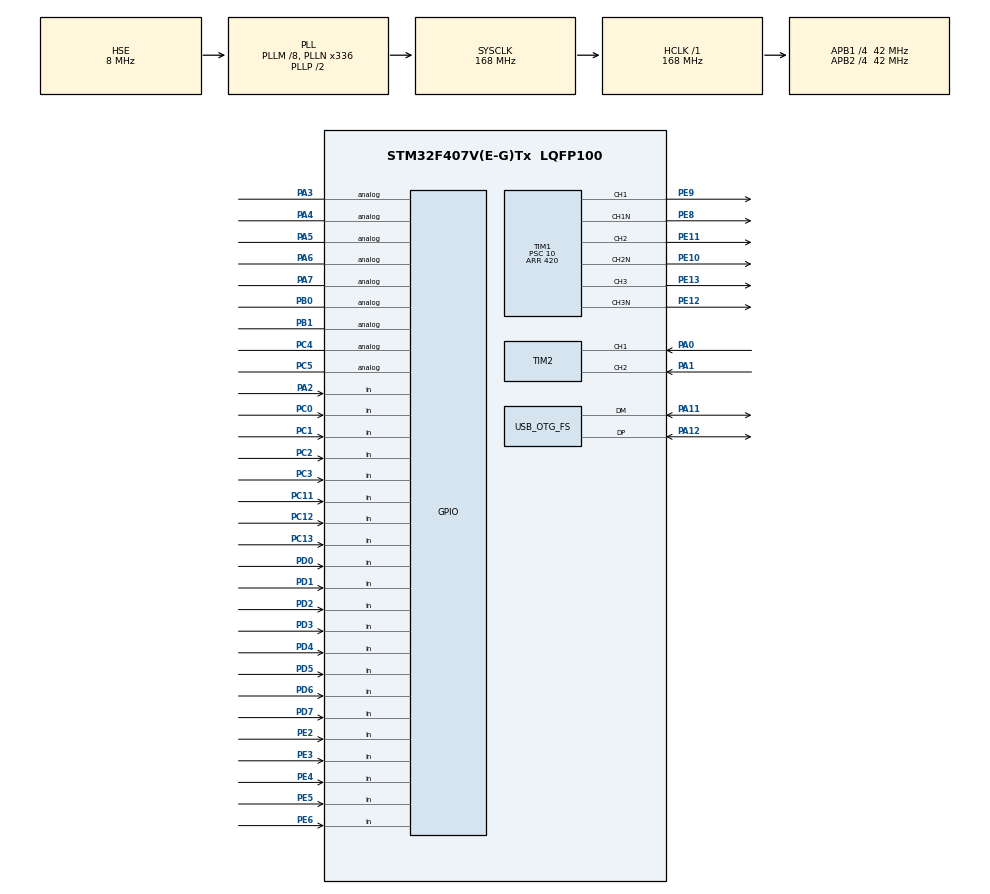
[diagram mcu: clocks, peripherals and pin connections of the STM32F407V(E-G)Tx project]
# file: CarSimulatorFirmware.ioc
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Mcu.Family=STM32F4
Mcu.Name=STM32F407V(E-G)Tx
Mcu.Package=LQFP100
NVIC.OTG_FS_IRQn=true\:0\:0\:false\:false\:true\:false\:true
NVIC.PriorityGroup=NVIC_PRIORITYGROUP_4
NVIC.TIM2_IRQn=true\:0\:0\:false\:false\:true\:true\:true
PA0-WKUP.GPIO_Speed=GPIO_SPEED_FREQ_VERY_HIGH
PA0-WKUP.Signal=S_TIM2_CH1_ETR
PA1.GPIO_Speed=GPIO_SPEED_FREQ_VERY_HIGH
PA1.Signal=S_TIM2_CH2
PA11.Mode=Device_Only
PA11.Signal=USB_OTG_FS_DM
PA12.Mode=Device_Only
PA12.Signal=USB_OTG_FS_DP
PA2.GPIO_PuPd=GPIO_NOPULL
PA2.Signal=GPIO_Input
PA3.Signal=GPIO_Analog
PA4.Signal=GPIO_Analog
PA5.Signal=GPIO_Analog
PA6.Signal=GPIO_Analog
PA7.Signal=GPIO_Analog
PB0.Signal=GPIO_Analog
PB1.Signal=GPIO_Analog
PC0.Signal=GPIO_Input
PC1.Signal=GPIO_Input
PC11.Signal=GPIO_Input
PC12.Signal=GPIO_Input
PC13-ANTI_TAMP.Signal=GPIO_Input
PC2.Signal=GPIO_Input
PC3.Signal=GPIO_Input
PC4.Signal=GPIO_Analog
PC5.Signal=GPIO_Analog
PD0.Signal=GPIO_Input
PD1.Signal=GPIO_Input
PD2.Signal=GPIO_Input
PD3.Signal=GPIO_Input
PD4.Signal=GPIO_Input
PD5.Signal=GPIO_Input
PD6.Signal=GPIO_Input
PD7.Signal=GPIO_Input
PE10.GPIO_Speed=GPIO_SPEED_FREQ_VERY_HIGH
PE10.Mode=PWM Generation2 CH2 CH2N
PE10.Signal=TIM1_CH2N
PE11.GPIO_Speed=GPIO_SPEED_FREQ_VERY_HIGH
PE11.Signal=S_TIM1_CH2
PE12.GPIO_Speed=GPIO_SPEED_FREQ_VERY_HIGH
PE12.Mode=PWM Generation3 CH3 CH3N
PE12.Signal=TIM1_CH3N
PE13.GPIO_Speed=GPIO_SPEED_FREQ_VERY_HIGH
PE13.Signal=S_TIM1_CH3
PE2.Signal=GPIO_Input
PE3.Signal=GPIO_Input
PE4.Signal=GPIO_Input
PE5.Signal=GPIO_Input
PE6.Signal=GPIO_Input
PE8.GPIO_Speed=GPIO_SPEED_FREQ_VERY_HIGH
PE8.Mode=PWM Generation1 CH1 CH1N
PE8.Signal=TIM1_CH1N
PE9.GPIO_PuPd=GPIO_NOPULL
PE9.GPIO_Speed=GPIO_SPEED_FREQ_VERY_HIGH
PE9.Signal=S_TIM1_CH1
PH0-OSC_IN.Mode=HSE-External-Oscillator
PH0-OSC_IN.Signal=RCC_OSC_IN
PH1-OSC_OUT.Mode=HSE-External-Oscillator
PH1-OSC_OUT.Signal=RCC_OSC_OUT
ProjectManager.HeapSize=0x200
ProjectManager.StackSize=0x400
ProjectManager.TargetToolchain=STM32CubeIDE
RCC.48MHZClocksFreq_Value=48000000
RCC.AHBFreq_Value=168000000
RCC.APB1CLKDivider=RCC_HCLK_DIV4
RCC.APB1Freq_Value=42000000
RCC.APB1TimFreq_Value=84000000
RCC.APB2CLKDivider=RCC_HCLK_DIV4
RCC.APB2Freq_Value=42000000
RCC.APB2TimFreq_Value=84000000
RCC.CortexFreq_Value=168000000
RCC.HCLKFreq_Value=168000000
RCC.HSE_VALUE=8000000
RCC.HSI_VALUE=16000000
RCC.LSE_VALUE=32768
RCC.PLLM=8
RCC.PLLN=336
RCC.PLLQ=7
RCC.SYSCLKFreq_VALUE=168000000
RCC.SYSCLKSource=RCC_SYSCLKSOURCE_PLLCLK
RCC.VCOOutputFreq_Value=336000000
SH.S_TIM1_CH1.0=TIM1_CH1,PWM Generation1 CH1 CH1N
SH.S_TIM1_CH2.0=TIM1_CH2,PWM Generation2 CH2 CH2N
SH.S_TIM1_CH3.0=TIM1_CH3,PWM Generation3 CH3 CH3N
SH.S_TIM2_CH1_ETR.0=TIM2_CH1,Encoder_Interface
SH.S_TIM2_CH2.0=TIM2_CH2,Encoder_Interface
TIM1.Channel-PWM\ Generation1\ CH1\ CH1N=TIM_CHANNEL_1
TIM1.Channel-PWM\ Generation2\ CH2\ CH2N=TIM_CHANNEL_2
TIM1.Channel-PWM\ Generation3\ CH3\ CH3N=TIM_CHANNEL_3
TIM1.Period=420
TIM1.Prescaler=10
TIM2.EncoderMode=TIM_ENCODERMODE_TI1
USB_DEVICE.CLASS_NAME_FS=CUSTOM_HID
USB_DEVICE.MANUFACTURER_STRING-CUSTOM_HID_FS=CZM Simluator
USB_DEVICE.PID_CUSTOMHID_FS=2020 
USB_DEVICE.PRODUCT_STRING_CUSTOMHID_FS=Car Simulator Firmware
USB_DEVICE.USBD_CUSTOMHID_OUTREPORT_BUF_SIZE-CUSTOM_HID_FS=64
USB_DEVICE.USBD_CUSTOM_HID_REPORT_DESC_SIZE-CUSTOM_HID_FS=64
USB_DEVICE.VID-CUSTOM_HID_FS=1203
USB_DEVICE.VirtualMode-CUSTOM_HID_FS=CustomHid
USB_DEVICE.VirtualModeFS=Custom_Hid_FS
USB_OTG_FS.VirtualMode=Device_Only
VP_TIM1_VS_ClockSourceINT.Mode=Internal
VP_USB_DEVICE_VS_USB_DEVICE_CUSTOM_HID_FS.Mode=CUSTOM_HID_FS
board=custom

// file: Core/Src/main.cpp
/* USER CODE BEGIN Header */
/**
  ******************************************************************************
  * @file           : main.c
  * @brief          : Main program body
  ******************************************************************************
  * @attention
  *
  * <h2><center>&copy; Copyright (c) 2020 STMicroelectronics.
  * All rights reserved.</center></h2>
  *
  * This software component is licensed by ST under Ultimate Liberty license
  * SLA0044, the "License"; You may not use this file except in compliance with
  * the License. You may obtain a copy of the License at:
  *                             www.st.com/SLA0044
  *
  ******************************************************************************
  */
/* USER CODE END Header */

#include "main.h"
//#include "usb_device.h"
#include "wheel_controller.h"
#include "encoder.h"
#include "utils.h"
#include  <stdio.h>

TIM_HandleTypeDef htim1;
TIM_HandleTypeDef htim2;

/* USER CODE BEGIN PV */
WheelController wheelController;
Encoder encoder;
int xAxisValue = 0, xAxisMaxValue = 32767, xAxisMinValue = -32768;
int encoderMaxValue = 1334*1.5;
uint8_t* usb_rx_buffer;
uint8_t report_id;
uint8_t report_type;
int counter =0;
/* USER CODE END PV */

void SystemClock_Config(void);
static void MX_GPIO_Init(void);
static void MX_TIM2_Init(void);
static void MX_TIM1_Init(void);

int main(void)
{

  /* MCU Configuration--------------------------------------------------------*/

  /* Reset of all peripherals, Initializes the Flash interface and the Systick. */
  HAL_Init();

  /* Configure the system clock */
  SystemClock_Config();

  /* Initialize all configured peripherals */
  MX_GPIO_Init();
  MX_TIM2_Init();
  MX_TIM1_Init();
  HAL_TIM_Encoder_Start(&htim2, TIM_CHANNEL_ALL);
  wheelController.begin();
  encoder.Encoder_Config();
  encoder.Encoder_Init();

//  MX_USB_DEVICE_Init();

  /* Infinite loop */
  /* USER CODE BEGIN WHILE */
  while (1)
  {

   encoder.update();
   if (encoder.encoderValue >= encoderMaxValue) {
	   xAxisValue = encoderMaxValue;
   } else if (encoder.encoderValue < -encoderMaxValue){
	   xAxisValue = -encoderMaxValue;
   } else {
	   xAxisValue = encoder.encoderValue;
   }
   counter++;

   wheelController.setX(mapInt(xAxisValue,-encoderMaxValue, encoderMaxValue, xAxisMinValue, xAxisMaxValue));
   wheelController.press(3);
   wheelController.update();
   HAL_GPIO_WritePin(GPIOD, GPIO_PIN_10, GPIO_PIN_SET );

  }
}

void SystemClock_Config(void)
{
  RCC_OscInitTypeDef RCC_OscInitStruct = {0};
  RCC_ClkInitTypeDef RCC_ClkInitStruct = {0};

  /** Configure the main internal regulator output voltage
  */
  __HAL_RCC_PWR_CLK_ENABLE();
  __HAL_PWR_VOLTAGESCALING_CONFIG(PWR_REGULATOR_VOLTAGE_SCALE1);
  /** Initializes the CPU, AHB and APB busses clocks
  */
  RCC_OscInitStruct.OscillatorType = RCC_OSCILLATORTYPE_HSE;
  RCC_OscInitStruct.HSEState = RCC_HSE_ON;
  RCC_OscInitStruct.PLL.PLLState = RCC_PLL_ON;
  RCC_OscInitStruct.PLL.PLLSource = RCC_PLLSOURCE_HSE;
  RCC_OscInitStruct.PLL.PLLM = 8;
  RCC_OscInitStruct.PLL.PLLN = 336;
  RCC_OscInitStruct.PLL.PLLP = RCC_PLLP_DIV2;
  RCC_OscInitStruct.PLL.PLLQ = 7;
  if (HAL_RCC_OscConfig(&RCC_OscInitStruct) != HAL_OK)
  {
    Error_Handler();
  }
  /** Initializes the CPU, AHB and APB busses clocks
  */
  RCC_ClkInitStruct.ClockType = RCC_CLOCKTYPE_HCLK|RCC_CLOCKTYPE_SYSCLK
                              |RCC_CLOCKTYPE_PCLK1|RCC_CLOCKTYPE_PCLK2;
  RCC_ClkInitStruct.SYSCLKSource = RCC_SYSCLKSOURCE_PLLCLK;
  RCC_ClkInitStruct.AHBCLKDivider = RCC_SYSCLK_DIV1;
  RCC_ClkInitStruct.APB1CLKDivider = RCC_HCLK_DIV4;
  RCC_ClkInitStruct.APB2CLKDivider = RCC_HCLK_DIV4;

  if (HAL_RCC_ClockConfig(&RCC_ClkInitStruct, FLASH_LATENCY_5) != HAL_OK)
  {
    Error_Handler();
  }
}

static void MX_TIM1_Init(void)
{

  TIM_ClockConfigTypeDef sClockSourceConfig = {0};
  TIM_MasterConfigTypeDef sMasterConfig = {0};
  TIM_OC_InitTypeDef sConfigOC = {0};
  TIM_BreakDeadTimeConfigTypeDef sBreakDeadTimeConfig = {0};

  htim1.Instance = TIM1;
  htim1.Init.Prescaler = 10;
  htim1.Init.CounterMode = TIM_COUNTERMODE_UP;
  htim1.Init.Period = 420;
  htim1.Init.ClockDivision = TIM_CLOCKDIVISION_DIV1;
  htim1.Init.RepetitionCounter = 0;
  htim1.Init.AutoReloadPreload = TIM_AUTORELOAD_PRELOAD_DISABLE;
  if (HAL_TIM_Base_Init(&htim1) != HAL_OK)
  {
    Error_Handler();
  }
  sClockSourceConfig.ClockSource = TIM_CLOCKSOURCE_INTERNAL;
  if (HAL_TIM_ConfigClockSource(&htim1, &sClockSourceConfig) != HAL_OK)
  {
    Error_Handler();
  }
  if (HAL_TIM_PWM_Init(&htim1) != HAL_OK)
  {
    Error_Handler();
  }
  sMasterConfig.MasterOutputTrigger = TIM_TRGO_RESET;
  sMasterConfig.MasterSlaveMode = TIM_MASTERSLAVEMODE_DISABLE;
  if (HAL_TIMEx_MasterConfigSynchronization(&htim1, &sMasterConfig) != HAL_OK)
  {
    Error_Handler();
  }
  sConfigOC.OCMode = TIM_OCMODE_PWM1;
  sConfigOC.Pulse = 0;
  sConfigOC.OCPolarity = TIM_OCPOLARITY_HIGH;
  sConfigOC.OCNPolarity = TIM_OCNPOLARITY_HIGH;
  sConfigOC.OCFastMode = TIM_OCFAST_DISABLE;
  sConfigOC.OCIdleState = TIM_OCIDLESTATE_RESET;
  sConfigOC.OCNIdleState = TIM_OCNIDLESTATE_RESET;
  if (HAL_TIM_PWM_ConfigChannel(&htim1, &sConfigOC, TIM_CHANNEL_1) != HAL_OK)
  {
    Error_Handler();
  }
  if (HAL_TIM_PWM_ConfigChannel(&htim1, &sConfigOC, TIM_CHANNEL_2) != HAL_OK)
  {
    Error_Handler();
  }
  if (HAL_TIM_PWM_ConfigChannel(&htim1, &sConfigOC, TIM_CHANNEL_3) != HAL_OK)
  {
    Error_Handler();
  }
  sBreakDeadTimeConfig.OffStateRunMode = TIM_OSSR_DISABLE;
  sBreakDeadTimeConfig.OffStateIDLEMode = TIM_OSSI_DISABLE;
  sBreakDeadTimeConfig.LockLevel = TIM_LOCKLEVEL_OFF;
  sBreakDeadTimeConfig.DeadTime = 0;
  sBreakDeadTimeConfig.BreakState = TIM_BREAK_DISABLE;
  sBreakDeadTimeConfig.BreakPolarity = TIM_BREAKPOLARITY_HIGH;
  sBreakDeadTimeConfig.AutomaticOutput = TIM_AUTOMATICOUTPUT_DISABLE;
  if (HAL_TIMEx_ConfigBreakDeadTime(&htim1, &sBreakDeadTimeConfig) != HAL_OK)
  {
    Error_Handler();
  }
  HAL_TIM_MspPostInit(&htim1);

}

static void MX_TIM2_Init(void)
{

  TIM_Encoder_InitTypeDef sConfig = {0};
  TIM_MasterConfigTypeDef sMasterConfig = {0};

  htim2.Instance = TIM2;
  htim2.Init.Prescaler = 0;
  htim2.Init.CounterMode = TIM_COUNTERMODE_UP;
  htim2.Init.Period = 0;
  htim2.Init.ClockDivision = TIM_CLOCKDIVISION_DIV1;
  htim2.Init.AutoReloadPreload = TIM_AUTORELOAD_PRELOAD_DISABLE;
  sConfig.EncoderMode = TIM_ENCODERMODE_TI12;
  sConfig.IC1Polarity = TIM_ICPOLARITY_RISING;
  sConfig.IC1Selection = TIM_ICSELECTION_DIRECTTI;
  sConfig.IC1Prescaler = TIM_ICPSC_DIV1;
  sConfig.IC1Filter = 0;
  sConfig.IC2Polarity = TIM_ICPOLARITY_RISING;
  sConfig.IC2Selection = TIM_ICSELECTION_DIRECTTI;
  sConfig.IC2Prescaler = TIM_ICPSC_DIV1;
  sConfig.IC2Filter = 0;
  if (HAL_TIM_Encoder_Init(&htim2, &sConfig) != HAL_OK)
  {
    Error_Handler();
  }
  sMasterConfig.MasterOutputTrigger = TIM_TRGO_RESET;
  sMasterConfig.MasterSlaveMode = TIM_MASTERSLAVEMODE_DISABLE;
  if (HAL_TIMEx_MasterConfigSynchronization(&htim2, &sMasterConfig) != HAL_OK)
  {
    Error_Handler();
  }

}

static void MX_GPIO_Init(void)
{
  GPIO_InitTypeDef GPIO_InitStruct = {0};

  /* GPIO Ports Clock Enable */
  __HAL_RCC_GPIOE_CLK_ENABLE();
  __HAL_RCC_GPIOC_CLK_ENABLE();
  __HAL_RCC_GPIOH_CLK_ENABLE();
  __HAL_RCC_GPIOA_CLK_ENABLE();
  __HAL_RCC_GPIOB_CLK_ENABLE();
  __HAL_RCC_GPIOD_CLK_ENABLE();

  /*Configure GPIO pins : PE2 PE3 PE4 PE5
                           PE6 */
  GPIO_InitStruct.Pin = GPIO_PIN_2|GPIO_PIN_3|GPIO_PIN_4|GPIO_PIN_5
                          |GPIO_PIN_6;
  GPIO_InitStruct.Mode = GPIO_MODE_INPUT;
  GPIO_InitStruct.Pull = GPIO_NOPULL;
  HAL_GPIO_Init(GPIOE, &GPIO_InitStruct);

  /*Configure GPIO pins : PC13 PC0 PC1 PC2
                           PC3 PC11 PC12 */
  GPIO_InitStruct.Pin = GPIO_PIN_13|GPIO_PIN_0|GPIO_PIN_1|GPIO_PIN_2
                          |GPIO_PIN_3|GPIO_PIN_11|GPIO_PIN_12;
  GPIO_InitStruct.Mode = GPIO_MODE_INPUT;
  GPIO_InitStruct.Pull = GPIO_NOPULL;
  HAL_GPIO_Init(GPIOC, &GPIO_InitStruct);

  /*Configure GPIO pin : PA2 */
  GPIO_InitStruct.Pin = GPIO_PIN_2;
  GPIO_InitStruct.Mode = GPIO_MODE_INPUT;
  GPIO_InitStruct.Pull = GPIO_NOPULL;
  HAL_GPIO_Init(GPIOA, &GPIO_InitStruct);

  /*Configure GPIO pins : PA3 PA4 PA5 PA6
                           PA7 */
  GPIO_InitStruct.Pin = GPIO_PIN_3|GPIO_PIN_4|GPIO_PIN_5|GPIO_PIN_6
                          |GPIO_PIN_7;
  GPIO_InitStruct.Mode = GPIO_MODE_ANALOG;
  GPIO_InitStruct.Pull = GPIO_NOPULL;
  HAL_GPIO_Init(GPIOA, &GPIO_InitStruct);

  /*Configure GPIO pins : PC4 PC5 */
  GPIO_InitStruct.Pin = GPIO_PIN_4|GPIO_PIN_5;
  GPIO_InitStruct.Mode = GPIO_MODE_ANALOG;
  GPIO_InitStruct.Pull = GPIO_NOPULL;
  HAL_GPIO_Init(GPIOC, &GPIO_InitStruct);

  /*Configure GPIO pins : PB0 PB1 */
  GPIO_InitStruct.Pin = GPIO_PIN_0|GPIO_PIN_1;
  GPIO_InitStruct.Mode = GPIO_MODE_ANALOG;
  GPIO_InitStruct.Pull = GPIO_NOPULL;
  HAL_GPIO_Init(GPIOB, &GPIO_InitStruct);

  /*Configure GPIO pins : PD0 PD1 PD2 PD3
                           PD4 PD5 PD6 PD7 */
  GPIO_InitStruct.Pin = GPIO_PIN_0|GPIO_PIN_1|GPIO_PIN_2|GPIO_PIN_3
                          |GPIO_PIN_4|GPIO_PIN_5|GPIO_PIN_6|GPIO_PIN_7;
  GPIO_InitStruct.Mode = GPIO_MODE_INPUT;
  GPIO_InitStruct.Pull = GPIO_NOPULL;
  HAL_GPIO_Init(GPIOD, &GPIO_InitStruct);

  GPIO_InitStruct.Pin = GPIO_PIN_10;
    GPIO_InitStruct.Mode = GPIO_MODE_OUTPUT_PP;
    GPIO_InitStruct.Pull = GPIO_NOPULL;
    HAL_GPIO_Init(GPIOD, &GPIO_InitStruct);

}

void Error_Handler(void)
{
}

/************************ (C) COPYRIGHT STMicroelectronics *****END OF FILE****/
